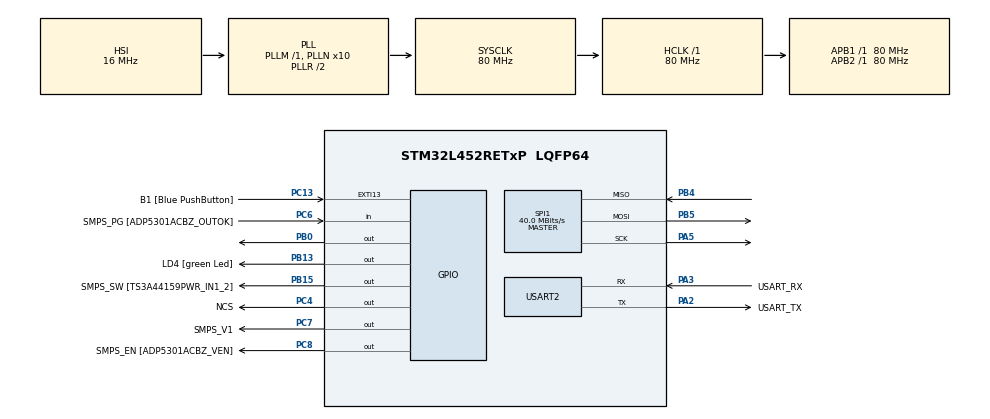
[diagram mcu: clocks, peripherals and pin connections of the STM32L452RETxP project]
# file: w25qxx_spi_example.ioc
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FREERTOS.Tasks01=defaultTask,24,128,StartDefaultTask,Default,NULL
Mcu.Family=STM32L4
Mcu.Name=STM32L452RETxP
Mcu.Package=LQFP64
NVIC.PriorityGroup=NVIC_PRIORITYGROUP_4
NVIC.TIM1_UP_TIM16_IRQn=true\:0\:0\:false\:false\:true\:false\:false\:true
NVIC.TimeBase=TIM1_UP_TIM16_IRQn
NVIC.TimeBaseIP=TIM1
PA13\ (JTMS/SWDIO).GPIO_Label=TMS
PA13\ (JTMS/SWDIO).Mode=Serial_Wire
PA13\ (JTMS/SWDIO).Signal=SYS_JTMS-SWDIO
PA14\ (JTCK/SWCLK).GPIO_Label=TCK
PA14\ (JTCK/SWCLK).Mode=Serial_Wire
PA14\ (JTCK/SWCLK).Signal=SYS_JTCK-SWCLK
PA2.GPIO_Label=USART_TX
PA2.GPIO_Mode=GPIO_MODE_AF_PP
PA2.GPIO_PuPd=GPIO_NOPULL
PA2.GPIO_Speed=GPIO_SPEED_FREQ_VERY_HIGH
PA2.Mode=Asynchronous
PA2.Signal=USART2_TX
PA3.GPIO_Label=USART_RX
PA3.GPIO_Mode=GPIO_MODE_AF_PP
PA3.GPIO_PuPd=GPIO_NOPULL
PA3.GPIO_Speed=GPIO_SPEED_FREQ_VERY_HIGH
PA3.Mode=Asynchronous
PA3.Signal=USART2_RX
PA5.Mode=Full_Duplex_Master
PA5.Signal=SPI1_SCK
PB0.GPIO_ModeDefaultOutputPP=GPIO_MODE_OUTPUT_PP
PB0.GPIO_PuPd=GPIO_NOPULL
PB0.Signal=GPIO_Output
PB13.GPIO_Label=LD4 [green Led]
PB13.Signal=GPIO_Output
PB15.GPIO_Label=SMPS_SW [TS3A44159PWR_IN1_2]
PB15.Signal=GPIO_Output
PB3\ (JTDO/TRACESWO).GPIO_Label=SWO
PB3\ (JTDO/TRACESWO).Signal=SYS_JTDO-SWO
PB4\ (NJTRST).GPIO_PuPd=GPIO_PULLUP
PB4\ (NJTRST).Mode=Full_Duplex_Master
PB4\ (NJTRST).Signal=SPI1_MISO
PB5.GPIO_PuPd=GPIO_PULLUP
PB5.Mode=Full_Duplex_Master
PB5.Signal=SPI1_MOSI
PC13.GPIO_Label=B1 [Blue PushButton]
PC13.GPIO_ModeDefaultEXTI=GPIO_MODE_IT_FALLING
PC13.GPIO_PuPd=GPIO_NOPULL
PC13.Signal=GPXTI13
PC14-OSC32_IN\ (PC14).Mode=LSE-External-Oscillator
PC14-OSC32_IN\ (PC14).Signal=RCC_OSC32_IN
PC15-OSC32_OUT\ (PC15).Mode=LSE-External-Oscillator
PC15-OSC32_OUT\ (PC15).Signal=RCC_OSC32_OUT
PC4.GPIO_Label=NCS
PC4.Signal=GPIO_Output
PC6.GPIO_Label=SMPS_PG [ADP5301ACBZ_OUTOK]
PC6.GPIO_PuPd=GPIO_PULLUP
PC6.Signal=GPIO_Input
PC7.GPIO_Label=SMPS_V1
PC7.GPIO_ModeDefaultOutputPP=GPIO_MODE_OUTPUT_PP
PC7.GPIO_PuPd=GPIO_NOPULL
PC7.GPIO_Speed=GPIO_SPEED_FREQ_LOW
PC7.Signal=GPIO_Output
PC8.GPIO_Label=SMPS_EN [ADP5301ACBZ_VEN]
PC8.Signal=GPIO_Output
PH0-OSC_IN\ (PH0).GPIO_Label=MCO
PH0-OSC_IN\ (PH0).Mode=HSE-External-Clock-Source
PH0-OSC_IN\ (PH0).Signal=RCC_OSC_IN
PH1-OSC_OUT\ (PH1).Signal=RCC_OSC_OUT
ProjectManager.HeapSize=0x200
ProjectManager.StackSize=0x400
ProjectManager.TargetToolchain=SW4STM32
RCC.ADCFreq_Value=64000000
RCC.AHBFreq_Value=80000000
RCC.APB1Freq_Value=80000000
RCC.APB1TimFreq_Value=80000000
RCC.APB2Freq_Value=80000000
RCC.APB2TimFreq_Value=80000000
RCC.CortexFreq_Value=80000000
RCC.HCLKFreq_Value=80000000
RCC.HSE_VALUE=8000000
RCC.HSI48_VALUE=48000000
RCC.HSI_VALUE=16000000
RCC.MSI_VALUE=4000000
RCC.PLLN=10
RCC.PLLSourceVirtual=RCC_PLLSOURCE_HSI
RCC.PREFETCH_ENABLE=1
RCC.SYSCLKFreq_VALUE=80000000
RCC.SYSCLKSource=RCC_SYSCLKSOURCE_PLLCLK
RCC.USBFreq_Value=64000000
RCC.VCOOutputFreq_Value=160000000
SPI1.BaudRatePrescaler=SPI_BAUDRATEPRESCALER_2
SPI1.CalculateBaudRate=40.0 MBits/s
SPI1.DataSize=SPI_DATASIZE_8BIT
SPI1.Direction=SPI_DIRECTION_2LINES
SPI1.Mode=SPI_MODE_MASTER
SPI1.NSSPMode=SPI_NSS_PULSE_DISABLE
SPI1.VirtualType=VM_MASTER
USART2.VirtualMode-Asynchronous=VM_ASYNC
VP_FREERTOS_VS_CMSIS_V2.Mode=CMSIS_V2
VP_SYS_VS_tim1.Mode=TIM1
board=NUCLEO-L452RE-P

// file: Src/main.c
/* USER CODE BEGIN Header */
/**
  ******************************************************************************
  * @file           : main.c
  * @brief          : Main program body
  ******************************************************************************
  * @attention
  *
  * <h2><center>&copy; Copyright (c) 2019 STMicroelectronics.
  * All rights reserved.</center></h2>
  *
  * This software component is licensed by ST under BSD 3-Clause license,
  * the "License"; You may not use this file except in compliance with the
  * License. You may obtain a copy of the License at:
  *                        opensource.org/licenses/BSD-3-Clause
  *
  ******************************************************************************
  */
/* USER CODE END Header */

#include "main.h"
#include "cmsis_os.h"
#include "spi.h"
#include "usart.h"
#include "gpio.h"

/* USER CODE BEGIN Includes */
#include "w25qxx.h"
/* USER CODE END Includes */

void SystemClock_Config(void);
void MX_FREERTOS_Init(void);

int main(void)
{

  /* MCU Configuration--------------------------------------------------------*/

  /* Reset of all peripherals, Initializes the Flash interface and the Systick. */
  HAL_Init();

  /* Configure the system clock */
  SystemClock_Config();

  /* Initialize all configured peripherals */
  MX_GPIO_Init();
  MX_USART2_UART_Init();
  MX_SPI1_Init();
  /* USER CODE BEGIN 2 */
  W25qxx_Init();
  /* USER CODE END 2 */

  /* Call init function for freertos objects (in freertos.c) */
  MX_FREERTOS_Init();

  /* Start scheduler */
  osKernelStart();

  /* We should never get here as control is now taken by the scheduler */

  /* Infinite loop */
  while (1)
  {

  }
}

void SystemClock_Config(void)
{
  RCC_OscInitTypeDef RCC_OscInitStruct = {0};
  RCC_ClkInitTypeDef RCC_ClkInitStruct = {0};
  RCC_PeriphCLKInitTypeDef PeriphClkInit = {0};

  /** Initializes the CPU, AHB and APB busses clocks
  */
  RCC_OscInitStruct.OscillatorType = RCC_OSCILLATORTYPE_HSI;
  RCC_OscInitStruct.HSIState = RCC_HSI_ON;
  RCC_OscInitStruct.HSICalibrationValue = RCC_HSICALIBRATION_DEFAULT;
  RCC_OscInitStruct.PLL.PLLState = RCC_PLL_ON;
  RCC_OscInitStruct.PLL.PLLSource = RCC_PLLSOURCE_HSI;
  RCC_OscInitStruct.PLL.PLLM = 1;
  RCC_OscInitStruct.PLL.PLLN = 10;
  RCC_OscInitStruct.PLL.PLLP = RCC_PLLP_DIV7;
  RCC_OscInitStruct.PLL.PLLQ = RCC_PLLQ_DIV2;
  RCC_OscInitStruct.PLL.PLLR = RCC_PLLR_DIV2;
  if (HAL_RCC_OscConfig(&RCC_OscInitStruct) != HAL_OK)
  {
    Error_Handler();
  }
  /** Initializes the CPU, AHB and APB busses clocks
  */
  RCC_ClkInitStruct.ClockType = RCC_CLOCKTYPE_HCLK|RCC_CLOCKTYPE_SYSCLK
                              |RCC_CLOCKTYPE_PCLK1|RCC_CLOCKTYPE_PCLK2;
  RCC_ClkInitStruct.SYSCLKSource = RCC_SYSCLKSOURCE_PLLCLK;
  RCC_ClkInitStruct.AHBCLKDivider = RCC_SYSCLK_DIV1;
  RCC_ClkInitStruct.APB1CLKDivider = RCC_HCLK_DIV1;
  RCC_ClkInitStruct.APB2CLKDivider = RCC_HCLK_DIV1;

  if (HAL_RCC_ClockConfig(&RCC_ClkInitStruct, FLASH_LATENCY_4) != HAL_OK)
  {
    Error_Handler();
  }
  PeriphClkInit.PeriphClockSelection = RCC_PERIPHCLK_USART2;
  PeriphClkInit.Usart2ClockSelection = RCC_USART2CLKSOURCE_PCLK1;
  if (HAL_RCCEx_PeriphCLKConfig(&PeriphClkInit) != HAL_OK)
  {
    Error_Handler();
  }
  /** Configure the main internal regulator output voltage
  */
  if (HAL_PWREx_ControlVoltageScaling(PWR_REGULATOR_VOLTAGE_SCALE1) != HAL_OK)
  {
    Error_Handler();
  }
}

void HAL_TIM_PeriodElapsedCallback(TIM_HandleTypeDef *htim)
{
  if (htim->Instance == TIM1) {
    HAL_IncTick();
  }
}

void Error_Handler(void)
{
}

/************************ (C) COPYRIGHT STMicroelectronics *****END OF FILE****/

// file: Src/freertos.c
/* USER CODE BEGIN Header */
/**
  ******************************************************************************
  * File Name          : freertos.c
  * Description        : Code for freertos applications
  ******************************************************************************
  * @attention
  *
  * <h2><center>&copy; Copyright (c) 2019 STMicroelectronics.
  * All rights reserved.</center></h2>
  *
  * This software component is licensed by ST under Ultimate Liberty license
  * SLA0044, the "License"; You may not use this file except in compliance with
  * the License. You may obtain a copy of the License at:
  *                             www.st.com/SLA0044
  *
  ******************************************************************************
  */
/* USER CODE END Header */

#include "FreeRTOS.h"
#include "task.h"
#include "main.h"
#include "cmsis_os.h"

/* USER CODE BEGIN Includes */
#include "w25qxx.h"
/* USER CODE END Includes */

osThreadId_t defaultTaskHandle;

void StartDefaultTask(void *argument);

void MX_FREERTOS_Init(void); /* (MISRA C 2004 rule 8.1) */

void MX_FREERTOS_Init(void) {
osKernelInitialize();

  /* Create the thread(s) */
  /* definition and creation of defaultTask */
  const osThreadAttr_t defaultTask_attributes = {
    .name = "defaultTask",
    .priority = (osPriority_t) osPriorityNormal,
    .stack_size = 128
  };
  defaultTaskHandle = osThreadNew(StartDefaultTask, NULL, &defaultTask_attributes);

}

void StartDefaultTask(void *argument)
{

  /* USER CODE BEGIN StartDefaultTask */
	static uint8_t pBuffer1[5] = {1,2,3,4,5};
	static uint8_t pBuffer2[5] = {0x00};
	W25qxx_EraseChip();
  /* Infinite loop */
  for(;;)
  {
	  W25qxx_ReadBytes(pBuffer2 ,0,sizeof(pBuffer2));
	  osDelay(1);
	  W25qxx_WritePage(pBuffer1, 0 , 0, sizeof(pBuffer1));
	  osDelay(1);
	  W25qxx_ReadBytes(pBuffer2 ,0,sizeof(pBuffer2));
	  osDelay(1);

  }
  /* USER CODE END StartDefaultTask */
}

/************************ (C) COPYRIGHT STMicroelectronics *****END OF FILE****/
